AUTOSAR XML (schema 4-2-2)
package /MICROSAR/BswM_swc
  mode declaration group ESH_RunRequest: initial-mode=RELEASED
    mode RELEASED
    mode REQUESTED
  mode declaration group BswMEcuResetMod: initial-mode=EcuResetDisabled
    mode EcuResetDisabled
    mode EcuResetEnabled
    mode EcuResetStarted
  data type mapping set BswMMappingSet  # Contains Mapping for ModeDeclarations Groups which are provided by BswM.
    mode-request-type-maps:
      implementation-data-type=BswM_ESH_RunRequest, mode-group=ESH_RunRequest
      implementation-data-type=BswM_BswMEcuResetMod, mode-group=BswMEcuResetMod
package /MICROSAR/BswM_swc/ComponentTypes
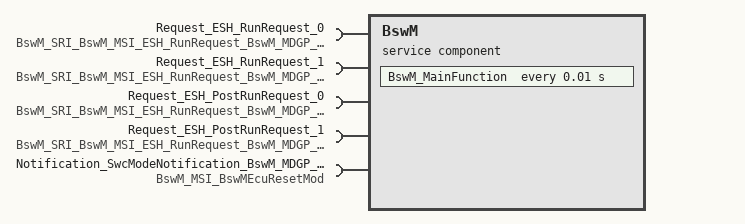
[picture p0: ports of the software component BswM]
  service sw component type BswM: category=SERVICE_COMPONENT
    5 x require port:
      Request_ESH_RunRequest_0: nonqueued-receiver-com-spec{data-element=BswM_SRI_BswM_MSI_ESH_RunRequest_BswM_MDGP_ESH_RunRequest/requestedMode, handle-out-of-range-status=SILENT, init-value=RELEASED}, required-interface=BswM_SRI_BswM_MSI_ESH_RunRequest_BswM_MDGP_ESH_RunRequest
      Request_ESH_RunRequest_1: nonqueued-receiver-com-spec{data-element=BswM_SRI_BswM_MSI_ESH_RunRequest_BswM_MDGP_ESH_RunRequest/requestedMode, handle-out-of-range-status=SILENT, init-value=RELEASED}, required-interface=BswM_SRI_BswM_MSI_ESH_RunRequest_BswM_MDGP_ESH_RunRequest
      Request_ESH_PostRunRequest_0: nonqueued-receiver-com-spec{data-element=BswM_SRI_BswM_MSI_ESH_RunRequest_BswM_MDGP_ESH_RunRequest/requestedMode, handle-out-of-range-status=SILENT, init-value=RELEASED}, required-interface=BswM_SRI_BswM_MSI_ESH_RunRequest_BswM_MDGP_ESH_RunRequest
      Request_ESH_PostRunRequest_1: nonqueued-receiver-com-spec{data-element=BswM_SRI_BswM_MSI_ESH_RunRequest_BswM_MDGP_ESH_RunRequest/requestedMode, handle-out-of-range-status=SILENT, init-value=RELEASED}, required-interface=BswM_SRI_BswM_MSI_ESH_RunRequest_BswM_MDGP_ESH_RunRequest
      Notification_SwcModeNotification_BswM_MDGP_BswMEcuResetMod: required-interface=BswM_MSI_BswMEcuResetMod
    behavior BswMInternalBehavior: data-type-mapping=BswMMappingSet, handle-termination-and-restart=NO-SUPPORT, included-data-type-set=data-type=[BswM_ESH_RunRequest, BswM_BswMEcuResetMod]
      timing event Timer_BswM_MainFunction: start-on-event=BswM_MainFunction, period=0.01
      port-api-options:
        enable-take-address=true, indirect-api=false, port=Notification_SwcModeNotification_BswM_MDGP_BswMEcuResetMod
        enable-take-address=true, indirect-api=false, port=Request_ESH_RunRequest_0
        enable-take-address=true, indirect-api=false, port=Request_ESH_RunRequest_1
        enable-take-address=true, indirect-api=false, port=Request_ESH_PostRunRequest_0
        enable-take-address=true, indirect-api=false, port=Request_ESH_PostRunRequest_1
      runnable BswM_MainFunction: mode-access-point=Notification_SwcModeNotification_BswM_MDGP_BswMEcuResetMod.BswM_MDGP_BswMEcuResetMod
        data-receive-point-by-arguments:
          4 x access:
            DataReceivePointBswM_MainFunction_Request_ESH_RunRequest_0_requestedMode: accessed-variable=Request_ESH_RunRequest_0.requestedMode
            DataReceivePointBswM_MainFunction_Request_ESH_RunRequest_1_requestedMode: accessed-variable=Request_ESH_RunRequest_1.requestedMode
            DataReceivePointBswM_MainFunction_Request_ESH_PostRunRequest_0_requestedMode: accessed-variable=Request_ESH_PostRunRequest_0.requestedMode
            DataReceivePointBswM_MainFunction_Request_ESH_PostRunRequest_1_requestedMode: accessed-variable=Request_ESH_PostRunRequest_1.requestedMode
  swc implementation BswMImplementation: programming-language=C, behavior=BswMInternalBehavior
package /MICROSAR/BswM_swc/DataTypes
  impl type BswM_ESH_RunRequest: compu {0=RELEASED, 1=REQUESTED}, implementation-data-type=uint8  # Unique value for each user
  impl type BswM_BswMEcuResetMod: compu {0=EcuResetDisabled, 1=EcuResetEnabled, 2=EcuResetStarted}, implementation-data-type=uint8  # Unique value for each user
package /MICROSAR/BswM_swc/Interfaces
  mode switch interface BswM_MSI_ESH_RunRequest: is-service=true, service-kind=BASIC-SOFTWARE-MODE-MANAGER
    mode group BswM_MDGP_ESH_RunRequest: type=ESH_RunRequest
  sender receiver interface BswM_SRI_BswM_MSI_ESH_RunRequest_BswM_MDGP_ESH_RunRequest: is-service=true, service-kind=BASIC-SOFTWARE-MODE-MANAGER
    data requestedMode: type=BswM_ESH_RunRequest
  mode switch interface BswM_MSI_BswMEcuResetMod: is-service=true, service-kind=BASIC-SOFTWARE-MODE-MANAGER
    mode group BswM_MDGP_BswMEcuResetMod: type=BswMEcuResetMod
  sender receiver interface BswM_SRI_BswM_MSI_BswMEcuResetMod_BswM_MDGP_BswMEcuResetMod: is-service=true, service-kind=BASIC-SOFTWARE-MODE-MANAGER
    data requestedMode: type=BswM_BswMEcuResetMod
